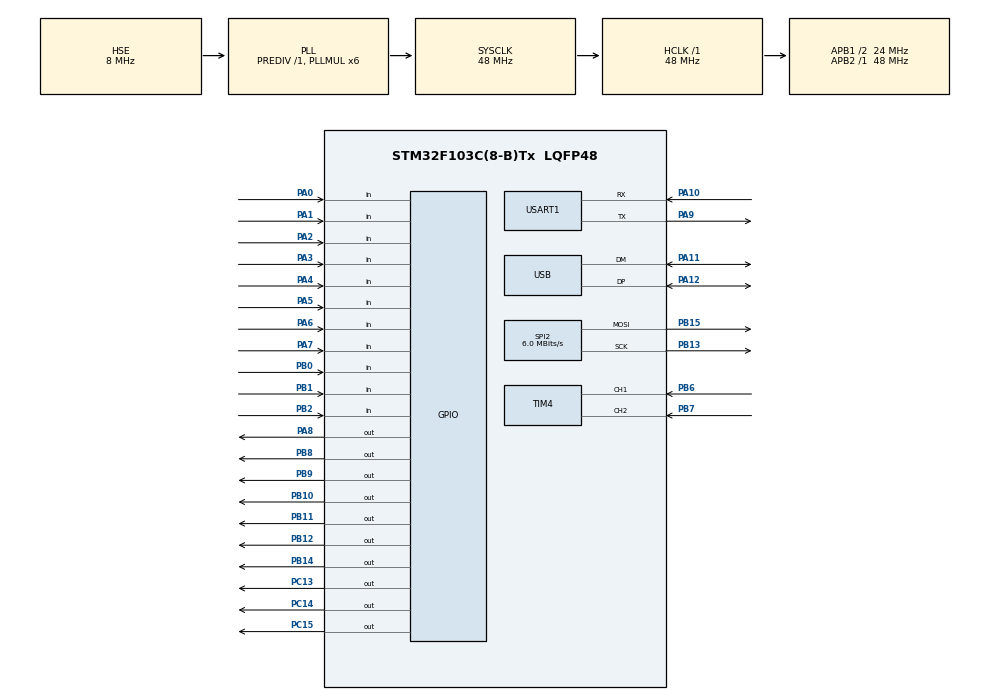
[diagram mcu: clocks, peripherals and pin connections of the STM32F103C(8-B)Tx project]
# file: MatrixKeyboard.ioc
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Dma.Request0=USART1_TX
Dma.Request1=SPI2_TX
Dma.SPI2_TX.1.Direction=DMA_MEMORY_TO_PERIPH
Dma.SPI2_TX.1.Instance=DMA1_Channel5
Dma.SPI2_TX.1.MemDataAlignment=DMA_MDATAALIGN_BYTE
Dma.SPI2_TX.1.MemInc=DMA_MINC_ENABLE
Dma.SPI2_TX.1.Mode=DMA_NORMAL
Dma.SPI2_TX.1.PeriphDataAlignment=DMA_PDATAALIGN_BYTE
Dma.SPI2_TX.1.PeriphInc=DMA_PINC_DISABLE
Dma.SPI2_TX.1.Priority=DMA_PRIORITY_MEDIUM
Dma.USART1_TX.0.Direction=DMA_MEMORY_TO_PERIPH
Dma.USART1_TX.0.Instance=DMA1_Channel4
Dma.USART1_TX.0.MemDataAlignment=DMA_MDATAALIGN_BYTE
Dma.USART1_TX.0.MemInc=DMA_MINC_ENABLE
Dma.USART1_TX.0.Mode=DMA_NORMAL
Dma.USART1_TX.0.PeriphDataAlignment=DMA_PDATAALIGN_BYTE
Dma.USART1_TX.0.PeriphInc=DMA_PINC_DISABLE
Dma.USART1_TX.0.Priority=DMA_PRIORITY_LOW
Mcu.Family=STM32F1
Mcu.Name=STM32F103C(8-B)Tx
Mcu.Package=LQFP48
NVIC.DMA1_Channel4_IRQn=true\:0\:0\:false\:false\:true\:false\:true
NVIC.DMA1_Channel5_IRQn=true\:0\:0\:false\:false\:true\:false\:true
NVIC.PriorityGroup=NVIC_PRIORITYGROUP_4
NVIC.TIM4_IRQn=true\:0\:0\:false\:false\:true\:true\:true
NVIC.USB_LP_CAN1_RX0_IRQn=true\:0\:0\:false\:false\:true\:false\:true
PA0-WKUP.GPIO_Mode=GPIO_MODE_INPUT
PA0-WKUP.GPIO_PuPd=GPIO_PULLDOWN
PA0-WKUP.Signal=GPIO_Input
PA1.GPIO_Mode=GPIO_MODE_INPUT
PA1.GPIO_PuPd=GPIO_PULLDOWN
PA1.Signal=GPIO_Input
PA10.Mode=Asynchronous
PA10.Signal=USART1_RX
PA11.Mode=Device
PA11.Signal=USB_DM
PA12.Mode=Device
PA12.Signal=USB_DP
PA13.Mode=Serial_Wire
PA13.Signal=SYS_JTMS-SWDIO
PA14.Mode=Serial_Wire
PA14.Signal=SYS_JTCK-SWCLK
PA2.GPIO_Mode=GPIO_MODE_INPUT
PA2.GPIO_PuPd=GPIO_PULLDOWN
PA2.Signal=GPIO_Input
PA3.GPIO_Mode=GPIO_MODE_INPUT
PA3.GPIO_PuPd=GPIO_PULLDOWN
PA3.Signal=GPIO_Input
PA4.GPIO_Mode=GPIO_MODE_INPUT
PA4.GPIO_PuPd=GPIO_PULLDOWN
PA4.Signal=GPIO_Input
PA5.GPIO_Mode=GPIO_MODE_INPUT
PA5.GPIO_PuPd=GPIO_PULLDOWN
PA5.Signal=GPIO_Input
PA6.GPIO_Mode=GPIO_MODE_INPUT
PA6.GPIO_PuPd=GPIO_PULLDOWN
PA6.Signal=GPIO_Input
PA7.GPIO_Mode=GPIO_MODE_INPUT
PA7.GPIO_PuPd=GPIO_PULLDOWN
PA7.Signal=GPIO_Input
PA8.GPIO_PuPd=GPIO_PULLDOWN
PA8.GPIO_Speed=GPIO_SPEED_FREQ_MEDIUM
PA8.Signal=GPIO_Output
PA9.Mode=Asynchronous
PA9.Signal=USART1_TX
PB0.GPIO_Mode=GPIO_MODE_INPUT
PB0.GPIO_PuPd=GPIO_PULLDOWN
PB0.Signal=GPIO_Input
PB1.GPIO_Mode=GPIO_MODE_INPUT
PB1.GPIO_PuPd=GPIO_PULLDOWN
PB1.Signal=GPIO_Input
PB10.GPIO_PuPd=GPIO_PULLDOWN
PB10.GPIO_Speed=GPIO_SPEED_FREQ_MEDIUM
PB10.Signal=GPIO_Output
PB11.GPIO_PuPd=GPIO_PULLDOWN
PB11.GPIO_Speed=GPIO_SPEED_FREQ_MEDIUM
PB11.Signal=GPIO_Output
PB12.GPIO_PuPd=GPIO_PULLDOWN
PB12.GPIO_Speed=GPIO_SPEED_FREQ_MEDIUM
PB12.Signal=GPIO_Output
PB13.Mode=TX_Only_Simplex_Unidirect_Master
PB13.Signal=SPI2_SCK
PB14.Signal=GPIO_Output
PB15.Mode=TX_Only_Simplex_Unidirect_Master
PB15.Signal=SPI2_MOSI
PB2.Signal=GPIO_Input
PB6.Signal=S_TIM4_CH1
PB7.Signal=S_TIM4_CH2
PB8.GPIO_PuPd=GPIO_PULLDOWN
PB8.GPIO_Speed=GPIO_SPEED_FREQ_MEDIUM
PB8.Signal=GPIO_Output
PB9.GPIO_PuPd=GPIO_PULLDOWN
PB9.GPIO_Speed=GPIO_SPEED_FREQ_MEDIUM
PB9.Signal=GPIO_Output
PC13-TAMPER-RTC.GPIO_PuPd=GPIO_PULLDOWN
PC13-TAMPER-RTC.GPIO_Speed=GPIO_SPEED_FREQ_MEDIUM
PC13-TAMPER-RTC.Signal=GPIO_Output
PC14-OSC32_IN.GPIO_PuPd=GPIO_PULLDOWN
PC14-OSC32_IN.GPIO_Speed=GPIO_SPEED_FREQ_MEDIUM
PC14-OSC32_IN.Signal=GPIO_Output
PC15-OSC32_OUT.GPIO_PuPd=GPIO_PULLDOWN
PC15-OSC32_OUT.GPIO_Speed=GPIO_SPEED_FREQ_MEDIUM
PC15-OSC32_OUT.Signal=GPIO_Output
PD0-OSC_IN.Mode=HSE-External-Oscillator
PD0-OSC_IN.Signal=RCC_OSC_IN
PD1-OSC_OUT.Mode=HSE-External-Oscillator
PD1-OSC_OUT.Signal=RCC_OSC_OUT
ProjectManager.HeapSize=0x200
ProjectManager.StackSize=0x400
ProjectManager.TargetToolchain=STM32CubeIDE
RCC.AHBFreq_Value=48000000
RCC.APB1CLKDivider=RCC_HCLK_DIV2
RCC.APB1Freq_Value=24000000
RCC.APB1TimFreq_Value=48000000
RCC.APB2Freq_Value=48000000
RCC.APB2TimFreq_Value=48000000
RCC.HCLKFreq_Value=48000000
RCC.PLLMUL=RCC_PLL_MUL6
RCC.SYSCLKFreq_VALUE=48000000
RCC.SYSCLKSource=RCC_SYSCLKSOURCE_PLLCLK
RCC.USBFreq_Value=48000000
SH.S_TIM4_CH1.0=TIM4_CH1,Encoder_Interface
SH.S_TIM4_CH2.0=TIM4_CH2,Encoder_Interface
SPI2.BaudRatePrescaler=SPI_BAUDRATEPRESCALER_4
SPI2.CalculateBaudRate=6.0 MBits/s
SPI2.Direction=SPI_DIRECTION_2LINES
SPI2.Mode=SPI_MODE_MASTER
SPI2.VirtualType=VM_MASTER
USART1.VirtualMode=VM_ASYNC
USB_DEVICE.CLASS_NAME_FS=CUSTOM_HID
USB_DEVICE.VirtualMode=CustomHid
USB_DEVICE.VirtualModeFS=Custom_Hid_FS
VP_USB_DEVICE_VS_USB_DEVICE_CUSTOM_HID_FS.Mode=CUSTOM_HID_FS
board=custom

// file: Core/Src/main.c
/* USER CODE BEGIN Header */
/**
  ******************************************************************************
  * @file           : main.c
  * @brief          : Main program body
  ******************************************************************************
  * @attention
  *
  * <h2><center>&copy; Copyright (c) 2021 STMicroelectronics.
  * All rights reserved.</center></h2>
  *
  * This software component is licensed by ST under BSD 3-Clause license,
  * the "License"; You may not use this file except in compliance with the
  * License. You may obtain a copy of the License at:
  *                        opensource.org/licenses/BSD-3-Clause
  *
  ******************************************************************************
  */
/* USER CODE END Header */
#include "main.h"
#include "usb_device.h"

/* USER CODE BEGIN Includes */
//#include "USB_Keyboard_Send.h"
#include "Keyboard_Task.h"
#include "RGB_WS2812_SPI.h"
#include "Keyboard_WS2812.h"
#include "SerialPrint.h"
/* USER CODE END Includes */

SPI_HandleTypeDef hspi2;
DMA_HandleTypeDef hdma_spi2_tx;
TIM_HandleTypeDef htim4;
UART_HandleTypeDef huart1;
DMA_HandleTypeDef hdma_usart1_tx;

/* USER CODE BEGIN PV */
//uint8_t HID_OutCompleteFlag;
extern USBD_HandleTypeDef hUsbDeviceFS;
/* USER CODE END PV */

void SystemClock_Config(void);

static void MX_GPIO_Init(void);

static void MX_DMA_Init(void);

static void MX_USART1_UART_Init(void);

static void MX_TIM4_Init(void);

static void MX_SPI2_Init(void);

int main(void) {

    /* MCU Configuration--------------------------------------------------------*/

    /* Reset of all peripherals, Initializes the Flash interface and the Systick. */
    HAL_Init();

    /* Configure the system clock */
    SystemClock_Config();

    /* Initialize all configured peripherals */
    MX_GPIO_Init();
    MX_DMA_Init();
    MX_USART1_UART_Init();
    MX_USB_DEVICE_Init();
    MX_TIM4_Init();
    MX_SPI2_Init();
    /* USER CODE BEGIN 2 */
    Keyboard_Init();
    /* USER CODE END 2 */

    /* Infinite loop */
    while (1) {
        /* USER CODE BEGIN 3 */
        Keyboard_Logic_Loop();

        //HAL_Delay(1);
    }
    /* USER CODE END 3 */
}

void SystemClock_Config(void) {
    RCC_OscInitTypeDef RCC_OscInitStruct = {0};
    RCC_ClkInitTypeDef RCC_ClkInitStruct = {0};
    RCC_PeriphCLKInitTypeDef PeriphClkInit = {0};

    /** Initializes the RCC Oscillators according to the specified parameters
    * in the RCC_OscInitTypeDef structure.
    */
    RCC_OscInitStruct.OscillatorType = RCC_OSCILLATORTYPE_HSE;
    RCC_OscInitStruct.HSEState = RCC_HSE_ON;
    RCC_OscInitStruct.HSEPredivValue = RCC_HSE_PREDIV_DIV1;
    RCC_OscInitStruct.HSIState = RCC_HSI_ON;
    RCC_OscInitStruct.PLL.PLLState = RCC_PLL_ON;
    RCC_OscInitStruct.PLL.PLLSource = RCC_PLLSOURCE_HSE;
    RCC_OscInitStruct.PLL.PLLMUL = RCC_PLL_MUL6;
    if (HAL_RCC_OscConfig(&RCC_OscInitStruct) != HAL_OK) {
        Error_Handler();
    }
    /** Initializes the CPU, AHB and APB buses clocks
    */
    RCC_ClkInitStruct.ClockType = RCC_CLOCKTYPE_HCLK | RCC_CLOCKTYPE_SYSCLK
                                  | RCC_CLOCKTYPE_PCLK1 | RCC_CLOCKTYPE_PCLK2;
    RCC_ClkInitStruct.SYSCLKSource = RCC_SYSCLKSOURCE_PLLCLK;
    RCC_ClkInitStruct.AHBCLKDivider = RCC_SYSCLK_DIV1;
    RCC_ClkInitStruct.APB1CLKDivider = RCC_HCLK_DIV2;
    RCC_ClkInitStruct.APB2CLKDivider = RCC_HCLK_DIV1;

    if (HAL_RCC_ClockConfig(&RCC_ClkInitStruct, FLASH_LATENCY_1) != HAL_OK) {
        Error_Handler();
    }
    PeriphClkInit.PeriphClockSelection = RCC_PERIPHCLK_USB;
    PeriphClkInit.UsbClockSelection = RCC_USBCLKSOURCE_PLL;
    if (HAL_RCCEx_PeriphCLKConfig(&PeriphClkInit) != HAL_OK) {
        Error_Handler();
    }
}

static void MX_SPI2_Init(void) {

    /* SPI2 parameter configuration*/
    hspi2.Instance = SPI2;
    hspi2.Init.Mode = SPI_MODE_MASTER;
    hspi2.Init.Direction = SPI_DIRECTION_2LINES;
    hspi2.Init.DataSize = SPI_DATASIZE_8BIT;
    hspi2.Init.CLKPolarity = SPI_POLARITY_LOW;
    hspi2.Init.CLKPhase = SPI_PHASE_1EDGE;
    hspi2.Init.NSS = SPI_NSS_SOFT;
    hspi2.Init.BaudRatePrescaler = SPI_BAUDRATEPRESCALER_4;
    hspi2.Init.FirstBit = SPI_FIRSTBIT_MSB;
    hspi2.Init.TIMode = SPI_TIMODE_DISABLE;
    hspi2.Init.CRCCalculation = SPI_CRCCALCULATION_DISABLE;
    hspi2.Init.CRCPolynomial = 10;
    if (HAL_SPI_Init(&hspi2) != HAL_OK) {
        Error_Handler();
    }

}

static void MX_TIM4_Init(void) {

    TIM_Encoder_InitTypeDef sConfig = {0};
    TIM_MasterConfigTypeDef sMasterConfig = {0};

    htim4.Instance = TIM4;
    htim4.Init.Prescaler = 0;
    htim4.Init.CounterMode = TIM_COUNTERMODE_UP;
    htim4.Init.Period = 65535;
    htim4.Init.ClockDivision = TIM_CLOCKDIVISION_DIV1;
    htim4.Init.AutoReloadPreload = TIM_AUTORELOAD_PRELOAD_DISABLE;
    sConfig.EncoderMode = TIM_ENCODERMODE_TI1;
    sConfig.IC1Polarity = TIM_ICPOLARITY_RISING;
    sConfig.IC1Selection = TIM_ICSELECTION_DIRECTTI;
    sConfig.IC1Prescaler = TIM_ICPSC_DIV1;
    sConfig.IC1Filter = 0;
    sConfig.IC2Polarity = TIM_ICPOLARITY_RISING;
    sConfig.IC2Selection = TIM_ICSELECTION_DIRECTTI;
    sConfig.IC2Prescaler = TIM_ICPSC_DIV1;
    sConfig.IC2Filter = 0;
    if (HAL_TIM_Encoder_Init(&htim4, &sConfig) != HAL_OK) {
        Error_Handler();
    }
    sMasterConfig.MasterOutputTrigger = TIM_TRGO_RESET;
    sMasterConfig.MasterSlaveMode = TIM_MASTERSLAVEMODE_DISABLE;
    if (HAL_TIMEx_MasterConfigSynchronization(&htim4, &sMasterConfig) != HAL_OK) {
        Error_Handler();
    }

}

static void MX_USART1_UART_Init(void) {

    huart1.Instance = USART1;
    huart1.Init.BaudRate = 115200;
    huart1.Init.WordLength = UART_WORDLENGTH_8B;
    huart1.Init.StopBits = UART_STOPBITS_1;
    huart1.Init.Parity = UART_PARITY_NONE;
    huart1.Init.Mode = UART_MODE_TX_RX;
    huart1.Init.HwFlowCtl = UART_HWCONTROL_NONE;
    huart1.Init.OverSampling = UART_OVERSAMPLING_16;
    if (HAL_UART_Init(&huart1) != HAL_OK) {
        Error_Handler();
    }

}

static void MX_DMA_Init(void) {

    /* DMA controller clock enable */
    __HAL_RCC_DMA1_CLK_ENABLE();

    /* DMA interrupt init */
    /* DMA1_Channel4_IRQn interrupt configuration */
    HAL_NVIC_SetPriority(DMA1_Channel4_IRQn, 0, 0);
    HAL_NVIC_EnableIRQ(DMA1_Channel4_IRQn);
    /* DMA1_Channel5_IRQn interrupt configuration */
    HAL_NVIC_SetPriority(DMA1_Channel5_IRQn, 0, 0);
    HAL_NVIC_EnableIRQ(DMA1_Channel5_IRQn);

}

static void MX_GPIO_Init(void) {
    GPIO_InitTypeDef GPIO_InitStruct = {0};

    /* GPIO Ports Clock Enable */
    __HAL_RCC_GPIOC_CLK_ENABLE();
    __HAL_RCC_GPIOD_CLK_ENABLE();
    __HAL_RCC_GPIOA_CLK_ENABLE();
    __HAL_RCC_GPIOB_CLK_ENABLE();

    /*Configure GPIO pin Output Level */
    HAL_GPIO_WritePin(GPIOC, GPIO_PIN_13 | GPIO_PIN_14 | GPIO_PIN_15, GPIO_PIN_RESET);

    /*Configure GPIO pin Output Level */
    HAL_GPIO_WritePin(GPIOB, GPIO_PIN_10 | GPIO_PIN_11 | GPIO_PIN_12 | GPIO_PIN_14
                             | GPIO_PIN_8 | GPIO_PIN_9, GPIO_PIN_RESET);

    /*Configure GPIO pin Output Level */
    HAL_GPIO_WritePin(GPIOA, GPIO_PIN_8, GPIO_PIN_RESET);

    /*Configure GPIO pins : PC13 PC14 PC15 */
    GPIO_InitStruct.Pin = GPIO_PIN_13 | GPIO_PIN_14 | GPIO_PIN_15;
    GPIO_InitStruct.Mode = GPIO_MODE_OUTPUT_PP;
    GPIO_InitStruct.Pull = GPIO_PULLDOWN;
    GPIO_InitStruct.Speed = GPIO_SPEED_FREQ_MEDIUM;
    HAL_GPIO_Init(GPIOC, &GPIO_InitStruct);

    /*Configure GPIO pins : PA0 PA1 PA2 PA3
                             PA4 PA5 PA6 PA7 */
    GPIO_InitStruct.Pin = GPIO_PIN_0 | GPIO_PIN_1 | GPIO_PIN_2 | GPIO_PIN_3
                          | GPIO_PIN_4 | GPIO_PIN_5 | GPIO_PIN_6 | GPIO_PIN_7;
    GPIO_InitStruct.Mode = GPIO_MODE_INPUT;
    GPIO_InitStruct.Pull = GPIO_PULLDOWN;
    HAL_GPIO_Init(GPIOA, &GPIO_InitStruct);

    /*Configure GPIO pins : PB0 PB1 */
    GPIO_InitStruct.Pin = GPIO_PIN_0 | GPIO_PIN_1;
    GPIO_InitStruct.Mode = GPIO_MODE_INPUT;
    GPIO_InitStruct.Pull = GPIO_PULLDOWN;
    HAL_GPIO_Init(GPIOB, &GPIO_InitStruct);

    /*Configure GPIO pin : PB2 */
    GPIO_InitStruct.Pin = GPIO_PIN_2;
    GPIO_InitStruct.Mode = GPIO_MODE_INPUT;
    GPIO_InitStruct.Pull = GPIO_NOPULL;
    HAL_GPIO_Init(GPIOB, &GPIO_InitStruct);

    /*Configure GPIO pins : PB10 PB11 PB12 PB8
                             PB9 */
    GPIO_InitStruct.Pin = GPIO_PIN_10 | GPIO_PIN_11 | GPIO_PIN_12 | GPIO_PIN_8
                          | GPIO_PIN_9;
    GPIO_InitStruct.Mode = GPIO_MODE_OUTPUT_PP;
    GPIO_InitStruct.Pull = GPIO_PULLDOWN;
    GPIO_InitStruct.Speed = GPIO_SPEED_FREQ_MEDIUM;
    HAL_GPIO_Init(GPIOB, &GPIO_InitStruct);

    /*Configure GPIO pin : PB14 */
    GPIO_InitStruct.Pin = GPIO_PIN_14;
    GPIO_InitStruct.Mode = GPIO_MODE_OUTPUT_PP;
    GPIO_InitStruct.Pull = GPIO_NOPULL;
    GPIO_InitStruct.Speed = GPIO_SPEED_FREQ_LOW;
    HAL_GPIO_Init(GPIOB, &GPIO_InitStruct);

    /*Configure GPIO pin : PA8 */
    GPIO_InitStruct.Pin = GPIO_PIN_8;
    GPIO_InitStruct.Mode = GPIO_MODE_OUTPUT_PP;
    GPIO_InitStruct.Pull = GPIO_PULLDOWN;
    GPIO_InitStruct.Speed = GPIO_SPEED_FREQ_MEDIUM;
    HAL_GPIO_Init(GPIOA, &GPIO_InitStruct);

}

void Error_Handler(void) {
    __disable_irq();
    while (1) {
    }
}

/************************ (C) COPYRIGHT STMicroelectronics *****END OF FILE****/
